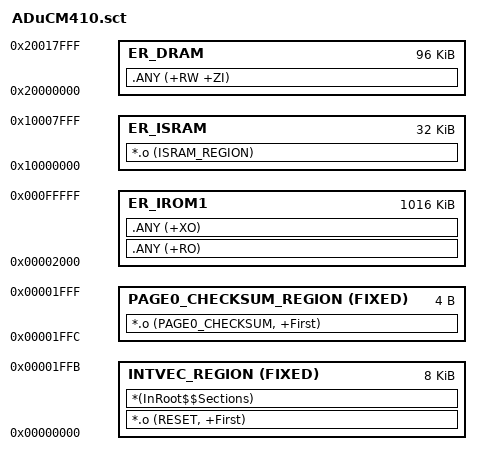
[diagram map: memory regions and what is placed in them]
; *************************************************************
; *** Scatter-Loading Description File generated by uVision ***
; *************************************************************

LR_IROM1 0x00000000    (1024 * 1024) {    ; load region size_region
	INTVEC_REGION 0x00000000 FIXED 0x1FFC 
	{
       *.o (RESET, +First)
		 *(InRoot$$Sections)
   }

   PAGE0_CHECKSUM_REGION 0x1FFC FIXED 0x4 
	{
       *.o (PAGE0_CHECKSUM, +First)
   }
	 
	ER_IROM1 0x00002000 ((1024 - 8) * 1024)  {  ; load address = execution address
   .ANY (+RO)
   .ANY (+XO)
  } 

  ER_ISRAM 0x10000000 (32 * 1024) {		; ISRAM used in SRAM mode 0
	*.o (ISRAM_REGION)
  }
  
  ER_DRAM 0x20000000  (96 *1024)  {  ; RW data
   .ANY (+RW +ZI)
  }
}




 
